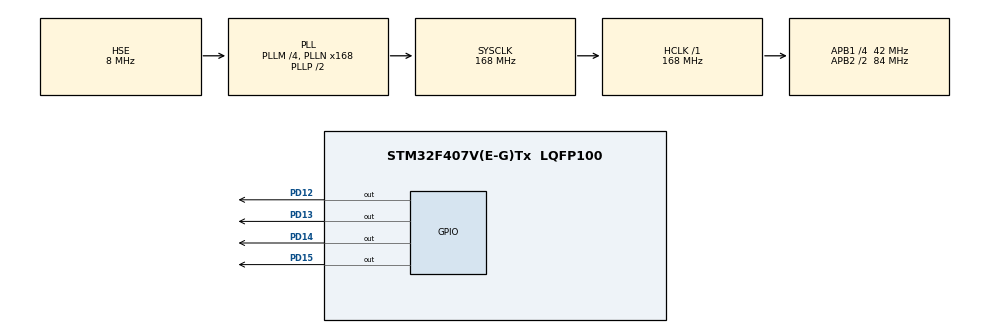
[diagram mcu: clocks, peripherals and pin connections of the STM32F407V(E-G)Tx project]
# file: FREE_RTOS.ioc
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FREERTOS.Tasks01=defaultTask,24,128,StartDefaultTask,Default,NULL,Dynamic,NULL,NULL;Task1,8,128,Task,Default,NULL,Dynamic,NULL,NULL;Task2,24,128,myTask2,Default,NULL,Dynamic,NULL,NULL;myTask04,32,128,StartTask04,Default,NULL,Dynamic,NULL,NULL;myTask05,32,128,StartTask05,Default,NULL,Dynamic,NULL,NULL
FREERTOS.configUSE_NEWLIB_REENTRANT=1
Mcu.Family=STM32F4
Mcu.Name=STM32F407V(E-G)Tx
Mcu.Package=LQFP100
NVIC.PriorityGroup=NVIC_PRIORITYGROUP_4
NVIC.TIM6_DAC_IRQn=true\:0\:0\:false\:false\:true\:false\:false\:true\:true
NVIC.TimeBase=TIM6_DAC_IRQn
NVIC.TimeBaseIP=TIM6
PD12.Signal=GPIO_Output
PD13.Signal=GPIO_Output
PD14.Signal=GPIO_Output
PD15.Signal=GPIO_Output
PH0-OSC_IN.Mode=HSE-External-Oscillator
PH0-OSC_IN.Signal=RCC_OSC_IN
PH1-OSC_OUT.Mode=HSE-External-Oscillator
PH1-OSC_OUT.Signal=RCC_OSC_OUT
ProjectManager.HeapSize=0x200
ProjectManager.StackSize=0x400
ProjectManager.TargetToolchain=STM32CubeIDE
RCC.48MHZClocksFreq_Value=48000000
RCC.AHBFreq_Value=168000000
RCC.APB1CLKDivider=RCC_HCLK_DIV4
RCC.APB1Freq_Value=42000000
RCC.APB1TimFreq_Value=84000000
RCC.APB2CLKDivider=RCC_HCLK_DIV2
RCC.APB2Freq_Value=84000000
RCC.APB2TimFreq_Value=168000000
RCC.CortexFreq_Value=168000000
RCC.HCLKFreq_Value=168000000
RCC.HSE_VALUE=8000000
RCC.HSI_VALUE=16000000
RCC.LSE_VALUE=32768
RCC.PLLM=4
RCC.PLLN=168
RCC.PLLQ=7
RCC.PLLSourceVirtual=RCC_PLLSOURCE_HSE
RCC.SYSCLKFreq_VALUE=168000000
RCC.SYSCLKSource=RCC_SYSCLKSOURCE_PLLCLK
RCC.VCOOutputFreq_Value=336000000
VP_FREERTOS_VS_CMSIS_V2.Mode=CMSIS_V2
VP_SYS_VS_tim6.Mode=TIM6
board=STM32F407G-DISC1

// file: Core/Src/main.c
/* USER CODE BEGIN Header */
/**
  ******************************************************************************
  * @file           : main.c
  * @brief          : Main program body
  ******************************************************************************
  * @attention
  *
  * Copyright (c) 2026 STMicroelectronics.
  * All rights reserved.
  *
  * This software is licensed under terms that can be found in the LICENSE file
  * in the root directory of this software component.
  * If no LICENSE file comes with this software, it is provided AS-IS.
  *
  ******************************************************************************
  */
/* USER CODE END Header */
#include "main.h"
#include "cmsis_os.h"

/* Definitions for defaultTask */
osThreadId_t defaultTaskHandle;
const osThreadAttr_t defaultTask_attributes = {
  .name = "defaultTask",
  .stack_size = 128 * 4,
  .priority = (osPriority_t) osPriorityNormal,
};
/* Definitions for Task1 */
osThreadId_t Task1Handle;
const osThreadAttr_t Task1_attributes = {
  .name = "Task1",
  .stack_size = 128 * 4,
  .priority = (osPriority_t) osPriorityLow,
};
/* Definitions for Task2 */
osThreadId_t Task2Handle;
const osThreadAttr_t Task2_attributes = {
  .name = "Task2",
  .stack_size = 128 * 4,
  .priority = (osPriority_t) osPriorityNormal,
};
/* Definitions for myTask04 */
osThreadId_t myTask04Handle;
const osThreadAttr_t myTask04_attributes = {
  .name = "myTask04",
  .stack_size = 128 * 4,
  .priority = (osPriority_t) osPriorityAboveNormal,
};
/* Definitions for myTask05 */
osThreadId_t myTask05Handle;
const osThreadAttr_t myTask05_attributes = {
  .name = "myTask05",
  .stack_size = 128 * 4,
  .priority = (osPriority_t) osPriorityAboveNormal,
};
/* USER CODE BEGIN PV */
osMessageQueueId_t myQueueHandle;
osSemaphoreId_t semHandle;

int arr[6] = {4,20,15,3,10,4};

int recvArr[6];
int rank;

/* USER CODE END PV */

void SystemClock_Config(void);
static void MX_GPIO_Init(void);
void StartDefaultTask(void *argument);
void Task(void *argument);
void myTask2(void *argument);
void StartTask04(void *argument);
void StartTask05(void *argument);

int main(void)
{

  /* MCU Configuration--------------------------------------------------------*/

  /* Reset of all peripherals, Initializes the Flash interface and the Systick. */
  HAL_Init();

  /* Configure the system clock */
  SystemClock_Config();

  /* Initialize all configured peripherals */
  MX_GPIO_Init();

  /* Init scheduler */
  osKernelInitialize();

  /* USER CODE BEGIN RTOS_SEMAPHORES */
  semHandle = osSemaphoreNew(1,1,NULL);
  /* USER CODE END RTOS_SEMAPHORES */

  /* USER CODE BEGIN RTOS_QUEUES */
  myQueueHandle = osMessageQueueNew(10, sizeof(int), NULL);
  /* USER CODE END RTOS_QUEUES */

  /* Create the thread(s) */
  /* creation of defaultTask */
  defaultTaskHandle = osThreadNew(StartDefaultTask, NULL, &defaultTask_attributes);

  /* creation of Task1 */
  Task1Handle = osThreadNew(Task, NULL, &Task1_attributes);

  /* creation of Task2 */
  Task2Handle = osThreadNew(myTask2, NULL, &Task2_attributes);

  /* creation of myTask04 */
  myTask04Handle = osThreadNew(StartTask04, NULL, &myTask04_attributes);

  /* creation of myTask05 */
  myTask05Handle = osThreadNew(StartTask05, NULL, &myTask05_attributes);

  /* Start scheduler */
  osKernelStart();

  /* We should never get here as control is now taken by the scheduler */

  /* Infinite loop */
  while (1)
  {

  }
}

void SystemClock_Config(void)
{
  RCC_OscInitTypeDef RCC_OscInitStruct = {0};
  RCC_ClkInitTypeDef RCC_ClkInitStruct = {0};

  /** Configure the main internal regulator output voltage
  */
  __HAL_RCC_PWR_CLK_ENABLE();
  __HAL_PWR_VOLTAGESCALING_CONFIG(PWR_REGULATOR_VOLTAGE_SCALE1);

  /** Initializes the RCC Oscillators according to the specified parameters
  * in the RCC_OscInitTypeDef structure.
  */
  RCC_OscInitStruct.OscillatorType = RCC_OSCILLATORTYPE_HSE;
  RCC_OscInitStruct.HSEState = RCC_HSE_ON;
  RCC_OscInitStruct.PLL.PLLState = RCC_PLL_ON;
  RCC_OscInitStruct.PLL.PLLSource = RCC_PLLSOURCE_HSE;
  RCC_OscInitStruct.PLL.PLLM = 4;
  RCC_OscInitStruct.PLL.PLLN = 168;
  RCC_OscInitStruct.PLL.PLLP = RCC_PLLP_DIV2;
  RCC_OscInitStruct.PLL.PLLQ = 7;
  if (HAL_RCC_OscConfig(&RCC_OscInitStruct) != HAL_OK)
  {
    Error_Handler();
  }

  /** Initializes the CPU, AHB and APB buses clocks
  */
  RCC_ClkInitStruct.ClockType = RCC_CLOCKTYPE_HCLK|RCC_CLOCKTYPE_SYSCLK
                              |RCC_CLOCKTYPE_PCLK1|RCC_CLOCKTYPE_PCLK2;
  RCC_ClkInitStruct.SYSCLKSource = RCC_SYSCLKSOURCE_PLLCLK;
  RCC_ClkInitStruct.AHBCLKDivider = RCC_SYSCLK_DIV1;
  RCC_ClkInitStruct.APB1CLKDivider = RCC_HCLK_DIV4;
  RCC_ClkInitStruct.APB2CLKDivider = RCC_HCLK_DIV2;

  if (HAL_RCC_ClockConfig(&RCC_ClkInitStruct, FLASH_LATENCY_5) != HAL_OK)
  {
    Error_Handler();
  }
}

static void MX_GPIO_Init(void)
{
  GPIO_InitTypeDef GPIO_InitStruct = {0};

  /* GPIO Ports Clock Enable */
  __HAL_RCC_GPIOH_CLK_ENABLE();
  __HAL_RCC_GPIOD_CLK_ENABLE();

  /*Configure GPIO pin Output Level */
  HAL_GPIO_WritePin(GPIOD, GPIO_PIN_12|GPIO_PIN_13|GPIO_PIN_14|GPIO_PIN_15, GPIO_PIN_RESET);

  /*Configure GPIO pins : PD12 PD13 PD14 PD15 */
  GPIO_InitStruct.Pin = GPIO_PIN_12|GPIO_PIN_13|GPIO_PIN_14|GPIO_PIN_15;
  GPIO_InitStruct.Mode = GPIO_MODE_OUTPUT_PP;
  GPIO_InitStruct.Pull = GPIO_NOPULL;
  GPIO_InitStruct.Speed = GPIO_SPEED_FREQ_LOW;
  HAL_GPIO_Init(GPIOD, &GPIO_InitStruct);

}

void StartDefaultTask(void *argument)
{
  for(;;)
  {
    osDelay(1);
  }
}

void Task(void *argument)
{
  for(;;)
  {
    osDelay(1);
  }
}

void myTask2(void *argument)
{
  for(;;)
  {
    osDelay(1);
  }
}

void StartTask04(void *argument)
{
  for(;;)
  {
    osDelay(1);
  }
}

void StartTask05(void *argument)
{
  for(;;)
  {
    osDelay(1);
  }
}

void HAL_TIM_PeriodElapsedCallback(TIM_HandleTypeDef *htim)
{
  if (htim->Instance == TIM6)
  {
    HAL_IncTick();
  }
}

void Error_Handler(void)
{
  __disable_irq();
  while (1)
  {
  }
}
